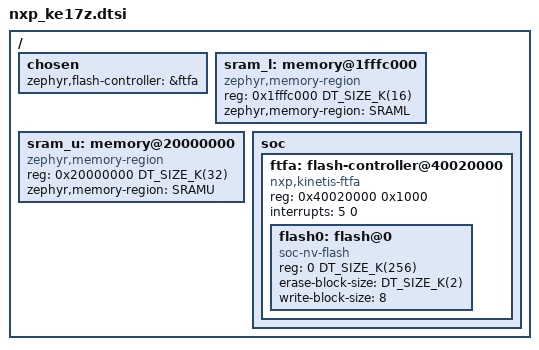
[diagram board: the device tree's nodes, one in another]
/*
 * Copyright 2024 NXP
 *
 * SPDX-License-Identifier: Apache-2.0
 */

#include <nxp/nxp_ke1xz.dtsi>

/delete-node/ &sram_l;
/delete-node/ &sram_u;

/ {
	chosen {
		zephyr,flash-controller = &ftfa;
	};

	/* Fix sram_l and sram_u, they have different addr and size on KE17Z */
	sram_l: memory@1fffc000 {
		compatible = "zephyr,memory-region", "mmio-sram";
		reg = <0x1fffc000 DT_SIZE_K(16)>;
		zephyr,memory-region = "SRAML";
	};

	sram_u: memory@20000000 {
		compatible = "zephyr,memory-region", "mmio-sram";
		reg = <0x20000000 DT_SIZE_K(32)>;
		zephyr,memory-region = "SRAMU";
	};

	soc{
		/* Remove ftfe, it doesn't exist on KE17Z */
		/delete-node/ ftfe;

		ftfa: flash-controller@40020000 {
			compatible = "nxp,kinetis-ftfa";
			reg = <0x40020000 0x1000>;
			interrupts = <5 0>;

			#address-cells = <1>;
			#size-cells = <1>;

			flash0: flash@0 {
				compatible = "soc-nv-flash";
				reg = <0 DT_SIZE_K(256)>;
				erase-block-size = <DT_SIZE_K(2)>;
				write-block-size = <8>;
			};
		};

		/* Remove rtc, it doesn't exist on KE17Z */
		/delete-node/ rtc@4003d000;
	};
};
